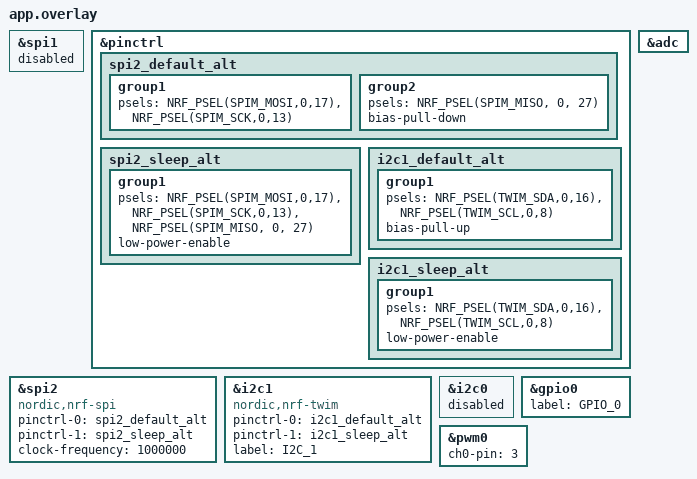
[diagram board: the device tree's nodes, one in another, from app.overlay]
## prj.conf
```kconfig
# Incresed stack due to settings API usage
CONFIG_SYSTEM_WORKQUEUE_STACK_SIZE=2048

CONFIG_BT=y
CONFIG_BT_DEBUG_LOG=y
# Security manager protocol support for pairing
CONFIG_BT_SMP=y
# used to sign authenticated data
CONFIG_BT_SIGNING=y
# select peripheral role
CONFIG_BT_PERIPHERAL=y
# enable GATT device information service
CONFIG_BT_DIS=n
# number of buffers available for GATT writing
CONFIG_BT_ATT_PREPARE_COUNT=5
# enable battery service
#CONFIG_BT_BAS=y
# clock control
CONFIG_CLOCK_CONTROL_NRF_K32SRC_RC=y
CONFIG_CLOCK_CONTROL_NRF_K32SRC_250PPM=y



# enable Heartrate service
#CONFIG_BT_HRS=y
# enables local privacy feature support (Random MAC)
CONFIG_BT_PRIVACY=n
# name that appears when browsing
CONFIG_BT_DEVICE_NAME="Microbit V2 BLE"
# https://specificationrefs.bluetooth.com/assigned-values/Appearance%20Values.pdf
# 833 = 0x341 = Heartrate belt
#CONFIG_BT_DEVICE_APPEARANCE=833
# 0x4c0 = generic control device = 1216
CONFIG_BT_DEVICE_APPEARANCE=1216
# disable updating of device name to prevent use of generic name
# enable run-time changing of device name
CONFIG_BT_DEVICE_NAME_DYNAMIC=n
CONFIG_BT_DEVICE_NAME_MAX=65

CONFIG_BT_KEYS_OVERWRITE_OLDEST=y
CONFIG_BT_SETTINGS=n
CONFIG_FLASH=y
CONFIG_FLASH_PAGE_LAYOUT=y
CONFIG_FLASH_MAP=y
CONFIG_NVS=y
CONFIG_SETTINGS=y


CONFIG_STDOUT_CONSOLE=y
CONFIG_CBPRINTF_FP_SUPPORT=y

CONFIG_STDOUT_CONSOLE=y
CONFIG_GPIO=y
CONFIG_SPI=y
CONFIG_SPI_NRFX=y
CONFIG_I2C=y
CONFIG_ADC=y
CONFIG_PWM=n
#need to turn these off for microbit v2 as they prevent low level fiddling with the i2c devices
CONFIG_LIS2DH=n
CONFIG_LIS2MDL=n
```

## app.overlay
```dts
/*
 *
 * SPDX-License-Identifier: Apache-2.0
 */
&spi1 {
	status = "disabled";
};

&pinctrl {
    /* IMPORTANT!  There should not be a space before the : in the next line (and similar below) */
    spi2_default_alt: spi2_default_alt {
        group1 {
            psels = <NRF_PSEL(SPIM_MOSI,0,17)>,
                    <NRF_PSEL(SPIM_SCK,0,13)>;
        };
        group2 {
        psels = <NRF_PSEL(SPIM_MISO, 0, 27)>;
        bias-pull-down;
        };
        
    };
    spi2_sleep_alt: spi2_sleep_alt {
        group1 {
            psels = <NRF_PSEL(SPIM_MOSI,0,17)>,
                    <NRF_PSEL(SPIM_SCK,0,13)>,
                    <NRF_PSEL(SPIM_MISO, 0, 27)>;
            low-power-enable;

        };
    };
    i2c1_default_alt: i2c1_default_alt {
        group1 {
            psels = <NRF_PSEL(TWIM_SDA,0,16)>,
                    <NRF_PSEL(TWIM_SCL,0,8)>;
            bias-pull-up;
        };
    };
    i2c1_sleep_alt: i2c1_sleep_alt {
        group1 {
            psels = <NRF_PSEL(TWIM_SDA,0,16)>,
                    <NRF_PSEL(TWIM_SCL,0,8)>;
            low-power-enable;
        };
    };
 };
 
 &spi2 {
    compatible = "nordic,nrf-spi";
    status = "okay";
    pinctrl-0 = <&spi2_default_alt>;
    pinctrl-1 = <&spi2_sleep_alt>;
    pinctrl-names = "default", "sleep";

    clock-frequency = <1000000>;
};
&i2c1 {
	compatible = "nordic,nrf-twim";
	status = "okay";
    pinctrl-0 = <&i2c1_default_alt>;
    pinctrl-1 = <&i2c1_sleep_alt>;
    pinctrl-names = "default", "sleep";
    label = "I2C_1";
    
	//sda-pin = < 16 >;   // P0.16 = I2C_INT_SDA
	//scl-pin = < 8 >;    // P0.8 = I2C_INT_SCL

};
&i2c0 {
    status="disabled";
};
&gpio0 {
    status="okay";
    label="GPIO_0";
};
&adc {
        status = "okay";
};
&pwm0 {
        status = "okay";
        ch0-pin = <3>; // P0.3 is labelled RING1 on the microbit. (connected to pin 1 in breakout board)
};
```

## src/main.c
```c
/* 
* SPDX-License-Identifier: Apache-2.0
*/
/* This example advertises three services:
 * 0x1800 Generic ACCESS (GAP)
 * 0x1801 Generic Attribute (GATT)
 * And a custom service 1-2-3-4-0 
 * This custom service contains a custom characteristic called stepcount_value
 * stepcount_value is updated on receipt of an interrupt from the LSM303 accelerometer.
 */
#include <zephyr/types.h>
#include <stddef.h>
#include <string.h>
#include <errno.h>
#include <zephyr/sys/printk.h>
#include <zephyr/sys/byteorder.h>
#include <zephyr/zephyr.h>

#include <zephyr/settings/settings.h>

#include <zephyr/bluetooth/bluetooth.h>
#include <zephyr/bluetooth/hci.h>
#include <zephyr/bluetooth/conn.h>
#include <zephyr/bluetooth/uuid.h>
#include <zephyr/bluetooth/gatt.h>
#include <zephyr/device.h>
#include <zephyr/drivers/sensor.h>
#include <stdio.h>

#include "lsm303_ll.h"



volatile int Subscribed = 0;
// ********************[ Start of First characteristic ]**************************************
#define BT_UUID_STEPCOUNT_ID  BT_UUID_128_ENCODE(1, 2, 3, 4, (uint64_t)5)
static struct bt_uuid_128 stepcount_id=BT_UUID_INIT_128(BT_UUID_STEPCOUNT_ID); // the 128 bit UUID for this gatt value
uint32_t stepcount_value=0; // the gatt characateristic value that is being shared over BLE	
static ssize_t read_stepcount(struct bt_conn *conn, const struct bt_gatt_attr *attr, void *buf, uint16_t len, uint16_t offset);
static ssize_t write_stepcount(struct bt_conn *conn, const struct bt_gatt_attr *attr, const void *buf, uint16_t len, uint16_t offset, uint8_t flags);
// Callback that is activated when the characteristic is read by central
static ssize_t read_stepcount(struct bt_conn *conn, const struct bt_gatt_attr *attr, void *buf, uint16_t len, uint16_t offset)
{
	printk("Got a read %d\n",stepcount_value);
	const char *value = (const char *)&stepcount_value; // point at the value in memory
	return bt_gatt_attr_read(conn, attr, buf, len, offset, value, sizeof(stepcount_value)); // pass the value back up through the BLE stack
}
// Callback that is activated when the characteristic is written by central
static ssize_t write_stepcount(struct bt_conn *conn, const struct bt_gatt_attr *attr,
			 const void *buf, uint16_t len, uint16_t offset,
			 uint8_t flags)
{
	uint8_t *value = attr->user_data;
	printk("Got a write %d\n",len);
	if (len == sizeof(stepcount_value)) // check that the incoming data is the correct size
	{
		memcpy(value, buf, len); // copy the incoming value in the memory occupied by our characateristic variable
	}
	else
	{
		printk("Write size is incorrect.  Received %d bytes, need %d\n",len,sizeof(stepcount_value));
	}
	return len;
}
// Arguments to BT_GATT_CHARACTERISTIC = _uuid, _props, _perm, _read, _write, _value
#define BT_GATT_CHAR1 BT_GATT_CHARACTERISTIC(&stepcount_id.uuid,BT_GATT_CHRC_READ | BT_GATT_CHRC_WRITE |  BT_GATT_CHRC_NOTIFY | BT_GATT_CCC_NOTIFY, BT_GATT_PERM_READ | BT_GATT_PERM_WRITE, read_stepcount, write_stepcount, &stepcount_value)
// ********************[ End of First characteristic ]****************************************
static void step_changed(const struct bt_gatt_attr *attr,
                                 uint16_t value)
{   if (value==BT_GATT_CCC_NOTIFY)
    {
       printk("Subscribed\n");
       Subscribed = 1;
    }
    else
    {
        printk("Not Subscribed\n");
        Subscribed = 0;
    }
}



// ********************[ Service definition ]********************
#define BT_UUID_CUSTOM_SERVICE_VAL	BT_UUID_128_ENCODE(1, 2, 3, 4, (uint64_t)0)
static struct bt_uuid_128 my_service_uuid = BT_UUID_INIT_128( BT_UUID_CUSTOM_SERVICE_VAL);
BT_GATT_SERVICE_DEFINE(my_service_svc,
	BT_GATT_PRIMARY_SERVICE(&my_service_uuid),
		BT_GATT_CHAR1,
        BT_GATT_CCC(step_changed,BT_GATT_PERM_READ | BT_GATT_PERM_WRITE)
);
// ********************[ Advertising configuration ]********************
/* The bt_data structure type:
 * {
 * 	uint8_t type : The kind of data encoded in the following structure
 * 	uint8_t data_len : the length of the data encoded
 * 	const uint8_t *data : a pointer to the data
 * }
 * This is used for encoding advertising data
*/
/* The BT_DATA_BYTES macro
 * #define BT_DATA_BYTES(_type, _bytes...) BT_DATA(_type, ((uint8_t []) { _bytes }), sizeof((uint8_t []) { _bytes }))
 * #define BT_DATA(_type, _data, _data_len) \
 *       { \
 *               .type = (_type), \
 *               .data_len = (_data_len), \
 *               .data = (const uint8_t *)(_data), \
 *       }
 * BT_DATA_UUID16_ALL : value indicates that all UUID's are listed in the advertising packet
*/
// bt_data is an array of data structures used in advertising. Each data structure is formatted as described above
static const struct bt_data ad[] = {
	BT_DATA_BYTES(BT_DATA_FLAGS, (BT_LE_AD_GENERAL | BT_LE_AD_NO_BREDR)), /* specify BLE advertising flags = discoverable, BR/EDR not supported (BLE only) */
	BT_DATA_BYTES(BT_DATA_UUID128_ALL, BT_UUID_CUSTOM_SERVICE_VAL /* A 128 Service UUID for the our custom service follows */),
};

struct bt_conn *active_conn=NULL; // use this to maintain a reference to the connection with the central device (if any)

// Callback that is activated when a connection with a central device is established
static void connected(struct bt_conn *conn, uint8_t err)
{
	if (err) {
		printk("Connection failed (err 0x%02x)\n", err);
	} else {
		printk("Connected\n");
		active_conn = conn;
	}
}
// Callback that is activated when a connection with a central device is taken down
static void disconnected(struct bt_conn *conn, uint8_t reason)
{
	printk("Disconnected (reason 0x%02x)\n", reason);
    Subscribed = 0;
	active_conn = NULL;
}
// structure used to pass connection callback handlers to the BLE stack
static struct bt_conn_cb conn_callbacks = {
	.connected = connected,
	.disconnected = disconnected,
};
// This is called when the BLE stack has finished initializing
static void bt_ready(void)
{
	int err;
	printk("Bluetooth initialized\n");

// start advertising see https://developer.nordicsemi.com/nRF_Connect_SDK/doc/latest/zephyr/reference/bluetooth/gap.html
/*
 * Excerpt from zephyr/include/bluetooth/bluetooth.h

 * #define BT_LE_ADV_CONN_NAME BT_LE_ADV_PARAM(BT_LE_ADV_OPT_CONNECTABLE | \
                                            BT_LE_ADV_OPT_USE_NAME, \
                                            BT_GAP_ADV_FAST_INT_MIN_2, \
                                            BT_GAP_ADV_FAST_INT_MAX_2, NULL)

 Also see : zephyr/include/bluetooth/gap.h for BT_GAP_ADV.... These set the advertising interval to between 100 and 150ms
 
 */
// Start BLE advertising using the ad array defined above
	err = bt_le_adv_start(BT_LE_ADV_CONN_NAME, ad, ARRAY_SIZE(ad), NULL, 0);
	if (err) {
		printk("Advertising failed to start (err %d)\n", err);
		return;
	}
	printk("Advertising successfully started\n");
}

void main(void)
{
	int err;
	int old_stepcount = 0;
	err = lsm303_ll_begin();
	if (err < 0)
	{
		 printk("\nError initializing lsm303.  Error code = %d\n",err);  
         while(1);

	}
	err = bt_enable(NULL);
	if (err) {
		printk("Bluetooth init failed (err %d)\n", err);
		return;
	}// bt_gatt_notify_uuid(active_conn,&stepcount_id,&my_service_svc.attrs[2], &stepcount_value,sizeof(stepcount_value));		
	bt_ready(); // This function starts advertising
	bt_conn_cb_register(&conn_callbacks);
	printk("Zephyr Microbit V2 minimal BLE example! %s\n", CONFIG_BOARD);
	if (lsm303_countSteps(&stepcount_value) < 0)
	{
		printk("Error starting step counter\n");
		while(1);
	}

	while (1) {
		k_msleep(100);		
		// int bt_gatt_notify(struct bt_conn *conn, const struct bt_gatt_attr *attr, const void *data, u16_t len)
		// conn: Connection object. (NULL for all)
		// attr: Characteristic Value Descriptor attribute.
		// data: Pointer to Attribute data.
		// len: Attribute value length.				
		if (active_conn)
		{
			if (stepcount_value != old_stepcount) // only send a notification if the data changes
			{
				old_stepcount = stepcount_value;	
                if (Subscribed)
                    bt_gatt_notify(active_conn,&my_service_svc.attrs[2], &stepcount_value,sizeof(stepcount_value));

			}
		}	
	}
}
```

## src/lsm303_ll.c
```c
#include <zephyr/sys/printk.h>
#include <zephyr/device.h>
#include <zephyr/drivers/gpio.h>
#include <zephyr/drivers/spi.h>
#include <zephyr/drivers/i2c.h>
#include <stdio.h>
#include <stdint.h>
#include "lsm303_ll.h"

static const struct device *gpio0;
static volatile uint32_t *pStepCount=NULL;
// The LSM303's interrupt output pin is connected to P0.25
#define STEP_INTERRUPT_PORT_BIT 25 
typedef void (*fptr)(void);



int lsm303_ll_readRegister(uint8_t RegNum, uint8_t *Value);
int lsm303_ll_writeRegister(uint8_t RegNum, uint8_t Value);
void readCalibrationData();
//static const struct spi_config * cfg;
static const struct device *i2c;
int lsm303_ll_begin()
{
	int nack;
	uint8_t device_id;
	// Set up the I2C interface
	i2c = device_get_binding("I2C_1");
	if (i2c==NULL)
	{
		printk("Error acquiring i2c1 interface\n");
		return -1;
	}	
	// Check to make sure the device is present by reading the WHO_AM_I register
	nack = lsm303_ll_readRegister(0x0f,&device_id);
	if (nack != 0)
	{
		printk("Error finding LSM303 on the I2C bus\n");
		return -2;
	}
	else	
	{
		printk("Found LSM303.  WHO_AM_I = %d\n",device_id);
	}
	lsm303_ll_writeRegister(0x20,0x77); //wake up LSM303 (max speed, all accel channels)
	lsm303_ll_writeRegister(0x23,0x08); //enable  high resolution mode +/- 2g
	
	return 0;
}
static struct gpio_callback stepcount_cb;
static void stepcount_handler(const struct device *dev, struct gpio_callback *cb, uint32_t pins)
{
	if (pStepCount != NULL)
	{
		*pStepCount = *pStepCount + 1;
		printk("step %x\n",*pStepCount);
	}	
}
int lsm303_countSteps(volatile uint32_t * pCount)
{
	if (pStepCount != NULL)
	{
		return -1; // counting already enabled
	}
	pStepCount = pCount;
	int ret;
	// Configure the GPIO's 	
	gpio0=device_get_binding("GPIO_0");
	if (gpio0 == NULL)
	{
		printk("Error acquiring GPIO 0 interface\n");
		return -2;
	}
	ret = gpio_pin_configure(gpio0,STEP_INTERRUPT_PORT_BIT,GPIO_INPUT | GPIO_PULL_UP);
	if (ret < 0)
	{
		printk("Error configuring step interrupt pin\n");
		return -3;
	}
	if (gpio_pin_interrupt_configure(gpio0,STEP_INTERRUPT_PORT_BIT,GPIO_INT_EDGE_FALLING) < 0)
	{
		printk("Error configuring interrupt for step count\n");
		return -4;
	}
	gpio_init_callback(&stepcount_cb, stepcount_handler, (1 << STEP_INTERRUPT_PORT_BIT) );	
    if (gpio_add_callback(gpio0, &stepcount_cb) < 0)
	{
		printk("Error adding callback for stepcount interrupt \n");
		return -5;
	}
	// All of the callback plumbing is now done
	// Need to configure the LSM303 to make it generate interrupt signals.
	lsm303_ll_writeRegister(0x22,0x40); // Send AOI1 interrupts to INT1 output
	lsm303_ll_writeRegister(0x30,0x80+0x15); // Interrupt on low accel on all 3 axes
	lsm303_ll_writeRegister(0x32,0x7f); // set the low accel threshold
	return 0;
}
int lsm303_ll_readAccelY()
{
	int16_t accel;
	uint8_t buf[2];
	buf[0] = 0x80+0x2a;	
	i2c_burst_read(i2c,LSM303_ACCEL_ADDRESS,0xaa, buf,2);
	accel = buf[1];
	accel = accel << 8;
	accel = accel + buf[0];
	accel = accel / 16; // must shift right 4 bits as this is a left justified 12 bit result
	// now scale to m^3/s * 100.
	// +2047 = +2g
	int accel_32bit = accel; // go to be wary of numeric overflow
	accel_32bit = accel_32bit * 2*981 / 2047;
    return accel_32bit;    
}

int lsm303_ll_readRegister(uint8_t RegNum, uint8_t *Value)
{
	    //reads a byte from a specific register
    int nack;   
	nack=i2c_reg_read_byte(i2c,LSM303_ACCEL_ADDRESS,RegNum,Value);
	return nack;
}
int lsm303_ll_writeRegister(uint8_t RegNum, uint8_t Value)
{
	//writes a byte to a specific register
    uint8_t Buffer[2];    
    Buffer[0]= Value;    
    int nack;    
	nack=i2c_reg_write_byte(i2c,LSM303_ACCEL_ADDRESS,RegNum,Value);
    return nack;
}
```
